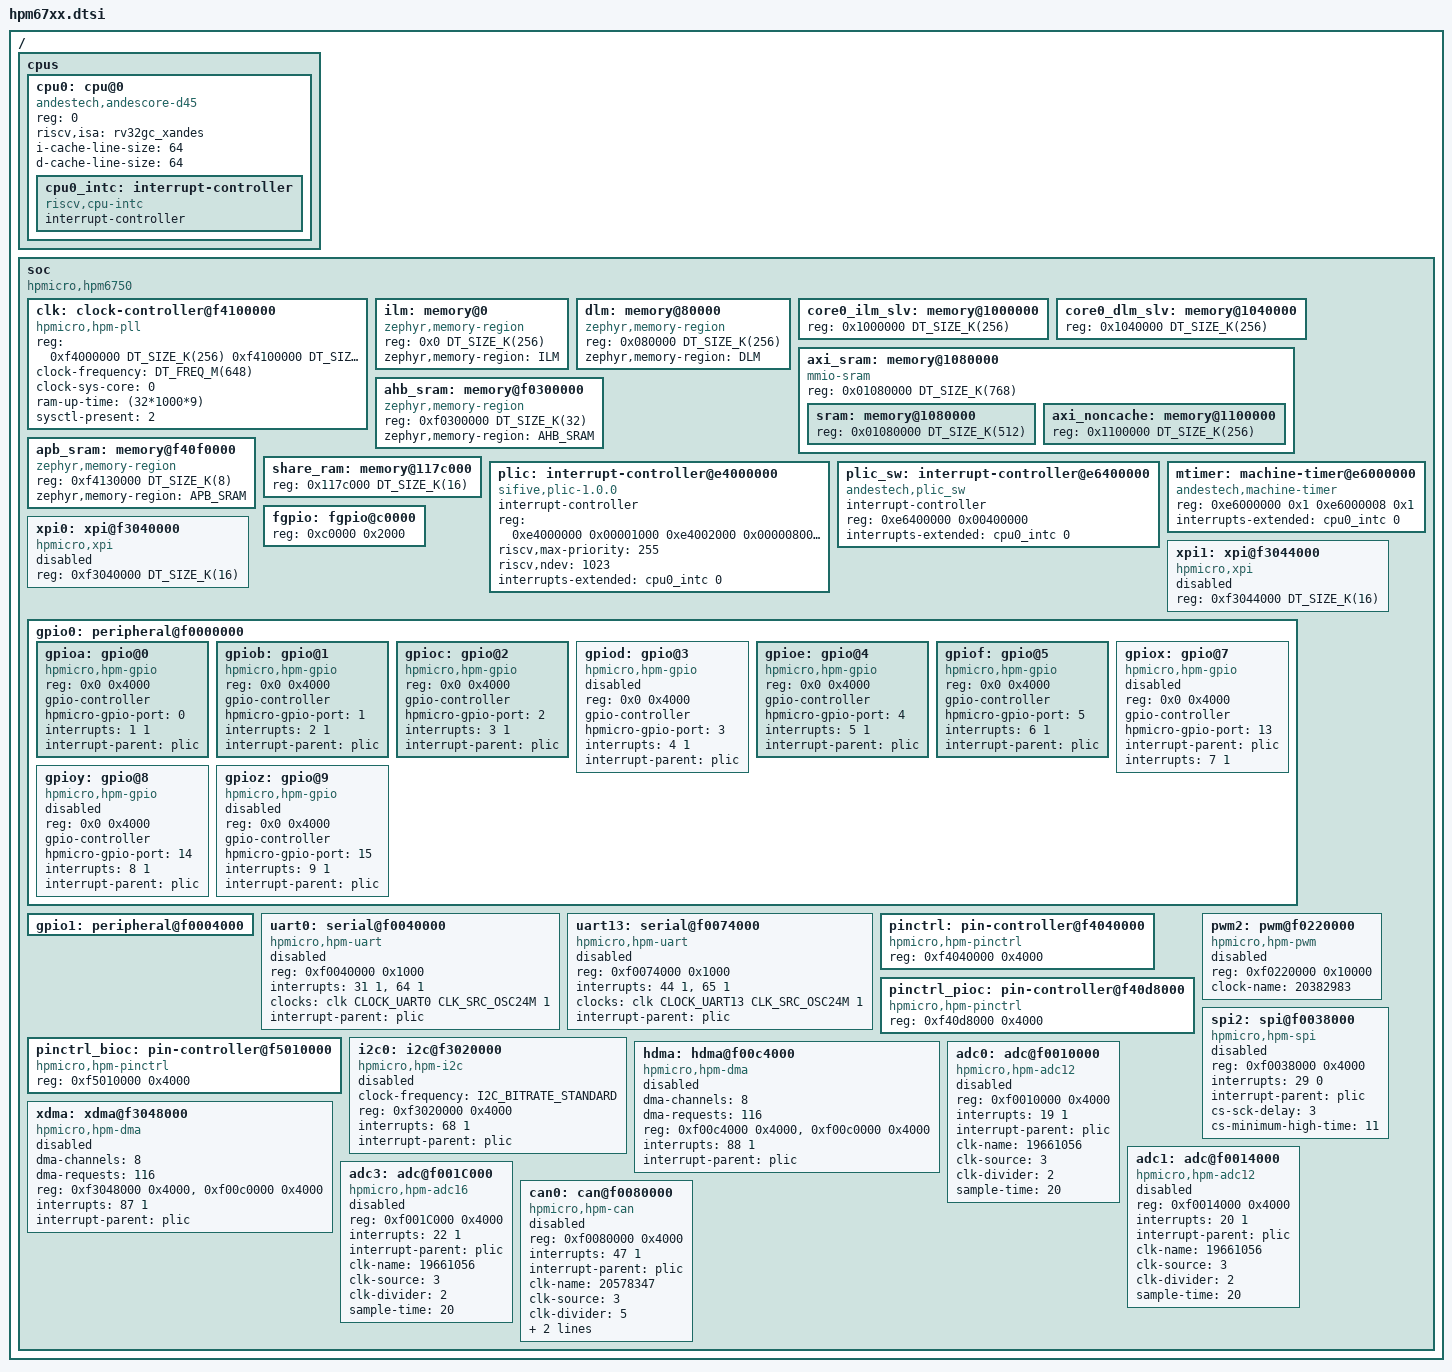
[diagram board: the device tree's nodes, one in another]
/*
 * Copyright 2023-2024 HPMicro
 * SPDX-License-Identifier: Apache-2.0
 */

/dts-v1/;
#include <zephyr/dt-bindings/gpio/gpio.h>
#include <zephyr/dt-bindings/i2c/i2c.h>
#include <zephyr/dt-bindings/pwm/pwm.h>
#include <dt-bindings/pwm/hpmicro-pwm-common.h>
#include <dt-bindings/clock/hpm6750-clocks.h>
#include <mem.h>
#include <freq.h>

/ {
	#address-cells = <1>;
	#size-cells = <1>;

	cpus {
		#address-cells = <1>;
		#size-cells = <0>;
		cpu0: cpu@0 {
			compatible = "andestech,andescore-d45", "riscv";
			reg = <0>;
			status = "okay";
			riscv,isa = "rv32gc_xandes";
			i-cache-line-size = <64>;
			d-cache-line-size = <64>;

			cpu0_intc: interrupt-controller {
				compatible = "riscv,cpu-intc";
				#address-cells = <0>;
				#interrupt-cells = <1>;
				interrupt-controller;
			};
		};
	};

	soc {
		#address-cells = <1>;
		#size-cells = <1>;
		compatible = "hpmicro,hpm6750";
		ranges;

		clk: clock-controller@f4100000 {
			compatible = "hpmicro,hpm-pll";
			reg = <0xf4000000 DT_SIZE_K(256)
				0xf4100000 DT_SIZE_K(256)>;
			clock-frequency = <DT_FREQ_M(648)>;
			reg-names = "sysctl", "pll";
			status = "okay";
			clock-sys-core = <0>;
			ram-up-time = <(32*1000*9)>;
			sysctl-present = <2>;
			#clock-cells = <3>;
		};

		ilm: memory@0 {
			compatible = "zephyr,memory-region";
			reg = <0x0 DT_SIZE_K(256)>;
			zephyr,memory-region = "ILM";
		};

		dlm: memory@80000 {
			compatible = "zephyr,memory-region";
			reg = <0x080000 DT_SIZE_K(256)>;
			zephyr,memory-region = "DLM";
		};

		core0_ilm_slv: memory@1000000 {
			reg = <0x1000000 DT_SIZE_K(256)>;
		};

		core0_dlm_slv: memory@1040000 {
			reg = <0x1040000 DT_SIZE_K(256)>;
		};

		axi_sram: memory@1080000 {
			compatible = "mmio-sram";
			reg = <0x01080000 DT_SIZE_K(768)>;
			#address-cells = <1>;
			#size-cells = <1>;
			sram: memory@1080000 {
				reg = <0x01080000 DT_SIZE_K(512)>;
			};
			axi_noncache: memory@1100000 {
				reg = <0x1100000 DT_SIZE_K(256)>;
			};
		};

		ahb_sram: memory@f0300000 {
			compatible = "zephyr,memory-region";
			reg = <0xf0300000 DT_SIZE_K(32)>;
			zephyr,memory-region = "AHB_SRAM";
		};

		apb_sram: memory@f40f0000 {
			compatible = "zephyr,memory-region";
			reg = <0xf4130000 DT_SIZE_K(8)>;
			zephyr,memory-region = "APB_SRAM";
		};

		share_ram: memory@117c000 {
			reg = <0x117c000 DT_SIZE_K(16)>;
		};

		plic: interrupt-controller@e4000000 {
			compatible = "sifive,plic-1.0.0";
			#address-cells = <1>;
			#interrupt-cells = <2>;
			interrupt-controller;
			reg = <	0xe4000000 0x00001000
				0xe4002000 0x00000800
				0xe4200000 0x00010000 >;
			reg-names = "prio", "irq_en", "reg";
			riscv,max-priority = <255>;
			riscv,ndev = <1023>;
			interrupts-extended = <&cpu0_intc 0>;
		};

		plic_sw: interrupt-controller@e6400000 {
			compatible = "andestech,plic_sw";
			#address-cells = <1>;
			#interrupt-cells = <2>;
			interrupt-controller;
			reg = <0xe6400000 0x00400000>;
			interrupts-extended = <&cpu0_intc 0>;
		};

		mtimer: machine-timer@e6000000 {
			compatible = "andestech,machine-timer";
			reg = <0xe6000000 0x1
			0xe6000008 0x1>;
			interrupts-extended = <&cpu0_intc 0>;
		};

		fgpio: fgpio@c0000 {
			reg = <0xc0000 0x2000>;
		};

		xpi0: xpi@f3040000 {
			compatible = "hpmicro,xpi";
			reg = <0xf3040000 DT_SIZE_K(16)>;
			#address-cells = <1>;
			#size-cells = <1>;
			status = "disabled";
		};

		xpi1: xpi@f3044000 {
			compatible = "hpmicro,xpi";
			reg = <0xf3044000 DT_SIZE_K(16)>;
			status = "disabled";
		};

		gpio0: peripheral@f0000000 {
			#address-cells = <1>;
			#size-cells = <1>;
			ranges = <0x0 0xf0000000 0x4000>;
		};

		gpio1: peripheral@f0004000 {
			#address-cells = <1>;
			#size-cells = <1>;
			ranges = <0x0 0xf0004000 0x4000>;
		};

		uart0: serial@f0040000 {
			compatible = "hpmicro,hpm-uart";
			reg = <0xf0040000 0x1000>;
			interrupts = <31 1>, <64 1>;
			interrupt-names = "uart", "idletimer";
			clocks = <&clk CLOCK_UART0 CLK_SRC_OSC24M 1>;
			interrupt-parent = <&plic>;
			status = "disabled";
		};

		uart13: serial@f0074000 {
			compatible = "hpmicro,hpm-uart";
			reg = <0xf0074000 0x1000>;
			interrupts = <44 1>, <65 1>;
			interrupt-names = "uart", "idletimer";
			clocks = <&clk CLOCK_UART13 CLK_SRC_OSC24M 1>;
			interrupt-parent = <&plic>;
			status = "disabled";
		};

		pinctrl: pin-controller@f4040000 {
			compatible = "hpmicro,hpm-pinctrl";
			reg = <0xf4040000 0x4000>;
			status = "okay";
		};

		pinctrl_pioc: pin-controller@f40d8000 {
			compatible = "hpmicro,hpm-pinctrl";
			reg = <0xf40d8000 0x4000>;
			status = "okay";
		};

		pinctrl_bioc: pin-controller@f5010000 {
			compatible = "hpmicro,hpm-pinctrl";
			reg = <0xf5010000 0x4000>;
			status = "okay";
		};

		pwm2: pwm@f0220000 {
			compatible = "hpmicro,hpm-pwm";
			reg = <0xf0220000 0x10000>;
			clock-name = <20382983>;
			status = "disabled";
			#pwm-cells = <3>;
		};

		i2c0: i2c@f3020000 {
			compatible = "hpmicro,hpm-i2c";
			#address-cells = <1>;
			#size-cells = <0>;
			clock-frequency = <I2C_BITRATE_STANDARD>;
			reg = <0xf3020000 0x4000>;
			interrupts = <68 1>;
			interrupt-parent = <&plic>;
			status = "disabled";
		};

		spi2: spi@f0038000 {
			compatible = "hpmicro,hpm-spi";
			reg = <0xf0038000 0x4000>;
			interrupts = <29 0>;
			interrupt-parent = <&plic>;
			status = "disabled";
			#address-cells = <1>;
			#size-cells = <0>;
			cs-sck-delay = <3>;
			cs-minimum-high-time = <11>;
		};

		hdma: hdma@f00c4000 {
			#dma-cells = <2>;
			compatible = "hpmicro,hpm-dma";
			dma-channels = <8>;
			dma-requests = <116>;
			reg = <0xf00c4000 0x4000>,
				<0xf00c0000 0x4000>; /* DMAMUX base */
			interrupts = <88 1>;
			interrupt-parent = <&plic>;
			status = "disabled";
		};

		xdma: xdma@f3048000 {
			#dma-cells = <2>;
			compatible = "hpmicro,hpm-dma";
			dma-channels = <8>;
			dma-requests = <116>;
			reg = <0xf3048000 0x4000>,
				<0xf00c0000 0x4000>; /* DMAMUX base */
			interrupts = <87 1>;
			interrupt-parent = <&plic>;
			status = "disabled";
		};

		adc0: adc@f0010000 {
			compatible = "hpmicro,hpm-adc12";
			reg = <0xf0010000 0x4000>;
			interrupts = <19 1>;
			interrupt-parent = <&plic>;
			clk-name = <19661056>;
			clk-source = <3>;
			clk-divider = <2>;
			sample-time = <20>;
			status = "disabled";
			#io-channel-cells = <1>;
		};

		adc1: adc@f0014000 {
			compatible = "hpmicro,hpm-adc12";
			reg = <0xf0014000 0x4000>;
			interrupts = <20 1>;
			interrupt-parent = <&plic>;
			clk-name = <19661056>;
			clk-source = <3>;
			clk-divider = <2>;
			sample-time = <20>;
			status = "disabled";
			#io-channel-cells = <1>;
		};

		adc3: adc@f001C000 {
			compatible = "hpmicro,hpm-adc16";
			reg = <0xf001C000 0x4000>;
			interrupts = <22 1>;
			interrupt-parent = <&plic>;
			clk-name = <19661056>;
			clk-source = <3>;
			clk-divider = <2>;
			sample-time = <20>;
			status = "disabled";
			#io-channel-cells = <1>;
		};

        can0: can@f0080000 {
            compatible = "hpmicro,hpm-can";
            reg = <0xf0080000 0x4000>;
            interrupts = <47 1>;
            interrupt-parent = <&plic>;
            clk-name = <20578347>;
            clk-source = <3>;
            clk-divider = <5>;
            bus-speed = <500000>;
            sjw = <1>;
            status = "disabled";
        };
	};
};

&gpio0 {
	gpioa: gpio@0 {
		compatible = "hpmicro,hpm-gpio";
		reg = <0x0 0x4000>;
		gpio-controller;
		#gpio-cells = <2>;
		hpmicro-gpio-port = <0>;
		interrupts = <1 1>;
		interrupt-parent = <&plic>;
	};

	gpiob: gpio@1 {
		compatible = "hpmicro,hpm-gpio";
		reg = <0x0 0x4000>;
		gpio-controller;
		#gpio-cells = <2>;
		hpmicro-gpio-port = <1>;
		interrupts = <2 1>;
		interrupt-parent = <&plic>;
	};

	gpioc: gpio@2 {
		compatible = "hpmicro,hpm-gpio";
		reg = <0x0 0x4000>;
		gpio-controller;
		#gpio-cells = <2>;
		hpmicro-gpio-port = <2>;
		interrupts = <3 1>;
		interrupt-parent = <&plic>;
	};

	gpiod: gpio@3 {
		compatible = "hpmicro,hpm-gpio";
		reg = <0x0 0x4000>;
		gpio-controller;
		#gpio-cells = <2>;
		status = "disabled";
		hpmicro-gpio-port = <3>;
		interrupts = <4 1>;
		interrupt-parent = <&plic>;
	};

	gpioe: gpio@4 {
		compatible = "hpmicro,hpm-gpio";
		reg = <0x0 0x4000>;
		gpio-controller;
		#gpio-cells = <2>;
		hpmicro-gpio-port = <4>;
		interrupts = <5 1>;
		interrupt-parent = <&plic>;
	};

	gpiof: gpio@5 {
		compatible = "hpmicro,hpm-gpio";
		reg = <0x0 0x4000>;
		gpio-controller;
		#gpio-cells = <2>;
		hpmicro-gpio-port = <5>;
		interrupts = <6 1>;
		interrupt-parent = <&plic>;
	};

	gpiox: gpio@7 {
		compatible = "hpmicro,hpm-gpio";
		reg = <0x0 0x4000>;
		gpio-controller;
		#gpio-cells = <2>;
		hpmicro-gpio-port = <13>;
		interrupt-parent = <&plic>;
		interrupts = <7 1>;
		status = "disabled";
	};

	gpioy: gpio@8 {
		compatible = "hpmicro,hpm-gpio";
		reg = <0x0 0x4000>;
		gpio-controller;
		#gpio-cells = <2>;
		hpmicro-gpio-port = <14>;
		interrupts = <8 1>;
		interrupt-parent = <&plic>;
		status = "disabled";
	};

	gpioz: gpio@9 {
		compatible = "hpmicro,hpm-gpio";
		reg = <0x0 0x4000>;
		gpio-controller;
		#gpio-cells = <2>;
		hpmicro-gpio-port = <15>;
		interrupts = <9 1>;
		interrupt-parent = <&plic>;
		status = "disabled";
	};
};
